AUTOSAR XML (schema 4-0-3)
standard types defined: Boolean, UInt16
package /AUTOSAR_Platform/DataConstrs
  range DC_Boolean: raw 0..1
  range DC_UInt16: raw 0..65535
package /PATAC/MSM/ComponentTypes
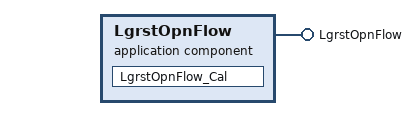
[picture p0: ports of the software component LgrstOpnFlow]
  application sw component type LgrstOpnFlow
    provide port LgrstOpnFlow: server-com-spec{operation=Cal, queue-length=1}, provided-interface=LgrstOpnFlow
    behavior LgrstOpnFlow_InternalBehavior
      operation invoked event OIT_LgrstOpnFlow_Cal_LgrstOpnFlow_Cal: start-on-event=LgrstOpnFlow_Cal, operation=LgrstOpnFlow.Cal
      runnable LgrstOpnFlow_Cal
  swc implementation LgrstOpnFlow_Implementation: behavior=LgrstOpnFlow_InternalBehavior
    code-descriptors:
      code Default: artifact-descriptors=autosar-engineering-object={short-label=Default, category=SWSRC}
package /PATAC/MSM/ModeAdjust/PortInterface
  client server interface LgrstOpnFlow
    operation Cal
      9 x arg, all with server-argument-impl-policy=USE-ARGUMENT-TYPE:
        LgrstUpwdDnwdPos: type=UInt16, direction=IN
        LgrstUpwdDnwdOpenPos1: type=UInt16, direction=IN
        LgrstUpwdStgDone: type=Boolean, direction=IN
        FtrstStgDone: type=Boolean, direction=IN
        LgrstInwdStgDone: type=Boolean, direction=IN
        Failflg: type=Boolean, direction=OUT
        LgrstInwdOtwdEn: type=Boolean, direction=OUT
        LgrstUpwdDnwdEn: type=Boolean, direction=OUT
        FtrstEn: type=Boolean, direction=OUT
